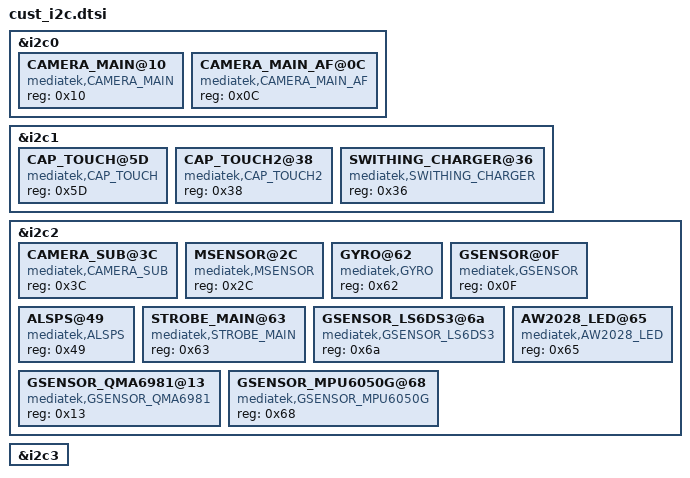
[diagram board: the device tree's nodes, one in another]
/*
 * Generated by MTK SP DrvGen Version 03.13.6 for MT6735M. Copyright MediaTek Inc. (C) 2013.
 * Sat Dec 24 14:58:27 2016
 * Do Not Modify the File.
 */

/*************************
 * I2C DTSI File
*************************/

&i2c0 {
	CAMERA_MAIN@10 {
		compatible = "mediatek,CAMERA_MAIN";
		reg = <0x10>;
	};

	CAMERA_MAIN_AF@0C {
		compatible = "mediatek,CAMERA_MAIN_AF";
		reg = <0x0C>;
	};

};

&i2c1 {
	CAP_TOUCH@5D {
		compatible = "mediatek,CAP_TOUCH";
		reg = <0x5D>;
	};

	CAP_TOUCH2@38 {
		compatible = "mediatek,CAP_TOUCH2";
		reg = <0x38>;
	};

	SWITHING_CHARGER@36 {
		compatible = "mediatek,SWITHING_CHARGER";
		reg = <0x36>;
	};

};

&i2c2 {
	CAMERA_SUB@3C {
		compatible = "mediatek,CAMERA_SUB";
		reg = <0x3C>;
	};

	MSENSOR@2C {
		compatible = "mediatek,MSENSOR";
		reg = <0x2C>;
	};

	GYRO@62 {
		compatible = "mediatek,GYRO";
		reg = <0x62>;
	};

	GSENSOR@0F {
		compatible = "mediatek,GSENSOR";
		reg = <0x0F>;
	};

	ALSPS@49 {
		compatible = "mediatek,ALSPS";
		reg = <0x49>;
	};

	STROBE_MAIN@63 {
		compatible = "mediatek,STROBE_MAIN";
		reg = <0x63>;
	};

	GSENSOR_LS6DS3@6a {
		compatible = "mediatek,GSENSOR_LS6DS3";
		reg = <0x6a>;
	};

	GSENSOR_QMA6981@13 {
		compatible = "mediatek,GSENSOR_QMA6981";
		reg = <0x13>;
	};

	GSENSOR_MPU6050G@68 {
		compatible = "mediatek,GSENSOR_MPU6050G";
		reg = <0x68>;
	};

	AW2028_LED@65 {
		compatible = "mediatek,AW2028_LED";
		reg = <0x65>;
	};

};

&i2c3 {
};

